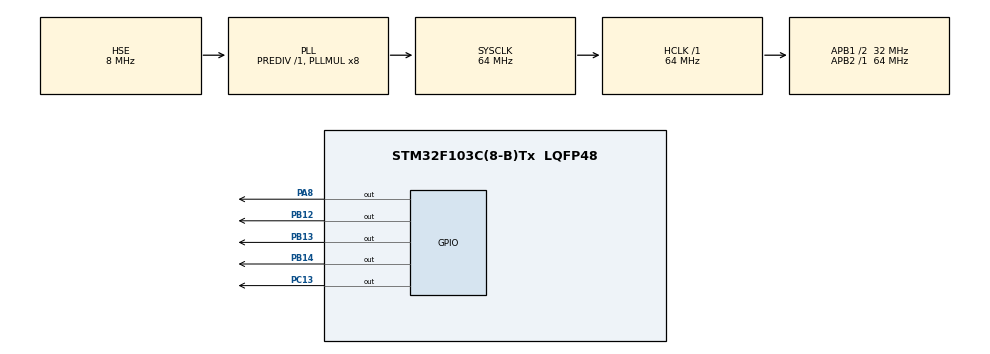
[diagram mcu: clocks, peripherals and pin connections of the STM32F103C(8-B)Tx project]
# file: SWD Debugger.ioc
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Mcu.Family=STM32F1
Mcu.Name=STM32F103C(8-B)Tx
Mcu.Package=LQFP48
NVIC.PriorityGroup=NVIC_PRIORITYGROUP_4
PA13.Mode=Serial_Wire
PA13.Signal=SYS_JTMS-SWDIO
PA14.Mode=Serial_Wire
PA14.Signal=SYS_JTCK-SWCLK
PA8.GPIO_PuPd=GPIO_PULLUP
PA8.GPIO_Speed=GPIO_SPEED_FREQ_HIGH
PA8.PinState=GPIO_PIN_SET
PA8.Signal=GPIO_Output
PB12.GPIO_Speed=GPIO_SPEED_FREQ_HIGH
PB12.PinState=GPIO_PIN_SET
PB12.Signal=GPIO_Output
PB13.GPIO_PuPd=GPIO_PULLUP
PB13.GPIO_Speed=GPIO_SPEED_FREQ_HIGH
PB13.Signal=GPIO_Output
PB14.GPIO_PuPd=GPIO_PULLUP
PB14.GPIO_Speed=GPIO_SPEED_FREQ_HIGH
PB14.PinState=GPIO_PIN_SET
PB14.Signal=GPIO_Output
PC13-TAMPER-RTC.GPIO_PuPd=GPIO_PULLUP
PC13-TAMPER-RTC.PinState=GPIO_PIN_SET
PC13-TAMPER-RTC.Signal=GPIO_Output
PD0-OSC_IN.Mode=HSE-External-Oscillator
PD0-OSC_IN.Signal=RCC_OSC_IN
PD1-OSC_OUT.Mode=HSE-External-Oscillator
PD1-OSC_OUT.Signal=RCC_OSC_OUT
ProjectManager.HeapSize=0x200
ProjectManager.StackSize=0x400
ProjectManager.TargetToolchain=SW4STM32
RCC.AHBFreq_Value=64000000
RCC.APB1CLKDivider=RCC_HCLK_DIV2
RCC.APB1Freq_Value=32000000
RCC.APB1TimFreq_Value=64000000
RCC.APB2Freq_Value=64000000
RCC.APB2TimFreq_Value=64000000
RCC.HCLKFreq_Value=64000000
RCC.PLLMUL=RCC_PLL_MUL8
RCC.PLLSourceVirtual=RCC_PLLSOURCE_HSE
RCC.SYSCLKFreq_VALUE=64000000
RCC.SYSCLKSource=RCC_SYSCLKSOURCE_PLLCLK
RCC.USBFreq_Value=64000000
board=custom

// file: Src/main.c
/**
  ******************************************************************************
  * @file           : main.c
  * @brief          : Main program body
  ******************************************************************************
  ** This notice applies to any and all portions of this file
  * that are not between comment pairs USER CODE BEGIN and
  * USER CODE END. Other portions of this file, whether
  * inserted by the user or by software development tools
  * are owned by their respective copyright owners.
  *
  * COPYRIGHT(c) 2018 STMicroelectronics
  *
  * Redistribution and use in source and binary forms, with or without modification,
  * are permitted provided that the following conditions are met:
  *   1. Redistributions of source code must retain the above copyright notice,
  *      this list of conditions and the following disclaimer.
  *   2. Redistributions in binary form must reproduce the above copyright notice,
  *      this list of conditions and the following disclaimer in the documentation
  *      and/or other materials provided with the distribution.
  *   3. Neither the name of STMicroelectronics nor the names of its contributors
  *      may be used to endorse or promote products derived from this software
  *      without specific prior written permission.
  *
  * THIS SOFTWARE IS PROVIDED BY THE COPYRIGHT HOLDERS AND CONTRIBUTORS "AS IS"
  * AND ANY EXPRESS OR IMPLIED WARRANTIES, INCLUDING, BUT NOT LIMITED TO, THE
  * IMPLIED WARRANTIES OF MERCHANTABILITY AND FITNESS FOR A PARTICULAR PURPOSE ARE
  * DISCLAIMED. IN NO EVENT SHALL THE COPYRIGHT HOLDER OR CONTRIBUTORS BE LIABLE
  * FOR ANY DIRECT, INDIRECT, INCIDENTAL, SPECIAL, EXEMPLARY, OR CONSEQUENTIAL
  * DAMAGES (INCLUDING, BUT NOT LIMITED TO, PROCUREMENT OF SUBSTITUTE GOODS OR
  * SERVICES; LOSS OF USE, DATA, OR PROFITS; OR BUSINESS INTERRUPTION) HOWEVER
  * CAUSED AND ON ANY THEORY OF LIABILITY, WHETHER IN CONTRACT, STRICT LIABILITY,
  * OR TORT (INCLUDING NEGLIGENCE OR OTHERWISE) ARISING IN ANY WAY OUT OF THE USE
  * OF THIS SOFTWARE, EVEN IF ADVISED OF THE POSSIBILITY OF SUCH DAMAGE.
  *
  ******************************************************************************
  */
#include "main.h"
#include "stm32f1xx_hal.h"

/* USER CODE BEGIN Includes */
//#include "debug.h"
#include "swdio.h"

uint16_t swdSwSeq;
uint8_t test8;
uint32_t *bitread=0;
volatile uint32_t *idCode=0;
uint32_t *bitread_lsb;
int testparity;
uint32_t status;

//Configure pin as output/input/open drain
/*
#define	_swdAsOuput()					\
		do{								\
			GPIO_InitTypeDef GPIO_InitStruct;	\
			HAL_GPIO_WritePin(SWD_IO_PORT, GPIO_PIN_8, GPIO_PIN_SET);	\
			GPIO_InitStruct.Pin = GPIO_PIN_8;	\
			GPIO_InitStruct.Mode = GPIO_MODE_OUTPUT_PP;	\
			GPIO_InitStruct.Pull = GPIO_PULLUP;	\
			GPIO_InitStruct.Speed = GPIO_SPEED_FREQ_HIGH; \
			HAL_GPIO_Init(SWD_IO_PORT, &GPIO_InitStruct);		\
		}while (0)

#define	_swdAsInput()					\
		do{								\
			GPIO_InitTypeDef GPIO_InitStruct;	\
			HAL_GPIO_WritePin(SWD_IO_PORT, GPIO_PIN_8, GPIO_PIN_SET);	\
			GPIO_InitStruct.Pin = GPIO_PIN_8;	\
			GPIO_InitStruct.Mode = GPIO_MODE_INPUT;	\
			GPIO_InitStruct.Pull = GPIO_PULLDOWN;	\
			GPIO_InitStruct.Speed = GPIO_SPEED_FREQ_HIGH; \
			HAL_GPIO_Init(SWD_IO_PORT, &GPIO_InitStruct);		\
		}while (0)

#define	_swdAsOuputOpenDrain()					\
		do{								\
			GPIO_InitTypeDef GPIO_InitStruct;	\
			HAL_GPIO_WritePin(SWD_IO_PORT, GPIO_PIN_8, GPIO_PIN_SET);	\
			GPIO_InitStruct.Pin = GPIO_PIN_8;	\
			GPIO_InitStruct.Mode = GPIO_MODE_OUTPUT_OD;	\
			GPIO_InitStruct.Pull = GPIO_PULLUP;	\
			GPIO_InitStruct.Speed = GPIO_SPEED_FREQ_HIGH; \
			HAL_GPIO_Init(SWD_IO_PORT, &GPIO_InitStruct);		\
		}while (0)
*/
/* USER CODE END Includes */

/* USER CODE BEGIN PV */
/* Private variables ---------------------------------------------------------*/

/* USER CODE END PV */

void SystemClock_Config(void);
static void MX_GPIO_Init(void);

/* USER CODE BEGIN PFP */
/* Private function prototypes -----------------------------------------------*/

/* USER CODE END PFP */

int main(void)
{

  /* MCU Configuration----------------------------------------------------------*/

  /* Reset of all peripherals, Initializes the Flash interface and the Systick. */

	HAL_Init();

  /* Configure the system clock */
  SystemClock_Config();

  /* Initialize all configured peripherals */
  MX_GPIO_Init();
  /* USER CODE BEGIN 2 */

  //resetDebugPin();
  //writeTurnAround();
  //testparity = computeParityBit(0x9);
  // All the initialization sequence
  //swdLineReset();
  //swdWriteBits(SW_EQ_CODE,16);
  //bitread = swdReadBits(32,*bitread_lsb);
  //swdLineReset();
  //swdWriteBits(1,2);
  //_swdAsInput();
  //bitread=swdReadBits(3,&idCode);

  lineReset();
  swdWriteBits(SW_EQ_CODE,16);
  lineReset();
  status=SwdApDpRequest(DP_RD_IDCODE,&bitread);
  //status=SwdApDpRequest(DP_RD_IDCODE,&bitread);

  //swdWriteBits(SW_IDCODE_RD,8);
  //bitread = SWDIO_Pin;

  //readTurnAround();
  //bitread=swdReadBits(38);

  //test8= SW_Request(0x01);
  //SW_ShiftPacket(SW_IDCODE_RD,0,0);
  //resetDebugPin();

  // Set the CDBGPWRUPREQ and CSYSPWRUPREQ bits of CTRL/STATUS
  //SW_ShiftPacket(0xA3,0,0x20000000);
  // Write 0x000000F0 to SELECT (select AHB-AP, bank 0xF)
  //SW_ShiftPacket(0xA9,0,0x000000F0);
  // Read the IDR CODE
  //SW_ShiftPacket(0xAF,0,0x000000F0);
  // Write 0x00000000 to SELECT (select AHB-AP, bank 0x0)
  //SW_ShiftPacket(0xA9,0,0x00000000);
  // Set the size field of CSW to 0x2 (32-bit transfer)
  //SW_ShiftPacket(0xAB,0,0x00000010);
  // Start using TAR/DRW to access internal memory
  //SW_ShiftPacket(0xAB,0,0x00000010);

  HAL_Delay(100);
  //bitread = tarWriteandReadAccess(0x20000000,0x12345678);

  // OxEOOEDF4 is the Debug Core Register Selector Register
  //init_ldr();
  //bitread = tarReadAccess(0xE000EDF4);

  // Try to write a data to it
  //writeTurnAround();
  //swdWriteBits(0xA1,8);				// 0x85 when is from LSB
  //readTurnAround();
  //swdReadBits(3);
  //writeTurnAround();
  //swdWriteBits(0x4A4A4A4A,34);		// 0x52 when is from LSB
  //resetDebugPin();
  //idleCycles(2);

  // Read the data from it
  //writeTurnAround();
  //swdWriteBits(0xA1,8);
  //readTurnAround();
  //swdReadBits(38);

  // Read the status flag from the status/control register
  //writeTurnAround();
  //swdWriteBits(SW_STATUS_FLG,8);
  //readTurnAround();
  //swdReadBits(38);
  //writeTurnAround();

  //bitread = returnIDcode(GPIOA,GPIO_PIN_8,GPIO_PIN_14);
  //bitread_lsb = bitread >> 15;
  // Write a data to a debug port
  // The 8 bit sequence : 1

  /* USER CODE END 2 */

  /* Infinite loop */
  while (1)
  {

  }

}

void SystemClock_Config(void)
{

  RCC_OscInitTypeDef RCC_OscInitStruct;
  RCC_ClkInitTypeDef RCC_ClkInitStruct;

    /**Initializes the CPU, AHB and APB busses clocks
    */
  RCC_OscInitStruct.OscillatorType = RCC_OSCILLATORTYPE_HSE;
  RCC_OscInitStruct.HSEState = RCC_HSE_ON;
  RCC_OscInitStruct.HSEPredivValue = RCC_HSE_PREDIV_DIV1;
  RCC_OscInitStruct.HSIState = RCC_HSI_ON;
  RCC_OscInitStruct.PLL.PLLState = RCC_PLL_ON;
  RCC_OscInitStruct.PLL.PLLSource = RCC_PLLSOURCE_HSE;
  RCC_OscInitStruct.PLL.PLLMUL = RCC_PLL_MUL8;
  if (HAL_RCC_OscConfig(&RCC_OscInitStruct) != HAL_OK)
  {
    _Error_Handler(__FILE__, __LINE__);
  }

    /**Initializes the CPU, AHB and APB busses clocks
    */
  RCC_ClkInitStruct.ClockType = RCC_CLOCKTYPE_HCLK|RCC_CLOCKTYPE_SYSCLK
                              |RCC_CLOCKTYPE_PCLK1|RCC_CLOCKTYPE_PCLK2;
  RCC_ClkInitStruct.SYSCLKSource = RCC_SYSCLKSOURCE_PLLCLK;
  RCC_ClkInitStruct.AHBCLKDivider = RCC_SYSCLK_DIV1;
  RCC_ClkInitStruct.APB1CLKDivider = RCC_HCLK_DIV2;
  RCC_ClkInitStruct.APB2CLKDivider = RCC_HCLK_DIV1;

  if (HAL_RCC_ClockConfig(&RCC_ClkInitStruct, FLASH_LATENCY_2) != HAL_OK)
  {
    _Error_Handler(__FILE__, __LINE__);
  }

    /**Configure the Systick interrupt time
    */
  HAL_SYSTICK_Config(HAL_RCC_GetHCLKFreq()/1000);

    /**Configure the Systick
    */
  HAL_SYSTICK_CLKSourceConfig(SYSTICK_CLKSOURCE_HCLK);

  /* SysTick_IRQn interrupt configuration */
  HAL_NVIC_SetPriority(SysTick_IRQn, 0, 0);
}

/** Configure pins as
        * Analog
        * Input
        * Output
        * EVENT_OUT
        * EXTI
*/
static void MX_GPIO_Init(void)
{

  GPIO_InitTypeDef GPIO_InitStruct;

  /* GPIO Ports Clock Enable */
  __HAL_RCC_GPIOC_CLK_ENABLE();
  __HAL_RCC_GPIOD_CLK_ENABLE();
  __HAL_RCC_GPIOB_CLK_ENABLE();
  __HAL_RCC_GPIOA_CLK_ENABLE();

  /*Configure GPIO pin Output Level */
  HAL_GPIO_WritePin(GPIOC, GPIO_PIN_13, GPIO_PIN_SET);

  /*Configure GPIO pin Output Level */
  HAL_GPIO_WritePin(SWD_CLOCK_PORT, GPIO_PIN_12|GPIO_PIN_14, GPIO_PIN_SET);

  /*Configure GPIO pin Output Level */
  HAL_GPIO_WritePin(SWD_CLOCK_PORT, GPIO_PIN_13, GPIO_PIN_RESET);

  /*Configure GPIO pin Output Level */
  HAL_GPIO_WritePin(SWD_IO_PORT, GPIO_PIN_8, GPIO_PIN_SET);

  /*Configure GPIO pin : PC13 */
  GPIO_InitStruct.Pin = GPIO_PIN_13;
  GPIO_InitStruct.Mode = GPIO_MODE_OUTPUT_PP;
  GPIO_InitStruct.Pull = GPIO_PULLUP;
  GPIO_InitStruct.Speed = GPIO_SPEED_FREQ_LOW;
  HAL_GPIO_Init(GPIOC, &GPIO_InitStruct);

  /*Configure GPIO pin : PB12 */
  GPIO_InitStruct.Pin = GPIO_PIN_12;
  GPIO_InitStruct.Mode = GPIO_MODE_OUTPUT_PP;
  GPIO_InitStruct.Pull = GPIO_NOPULL;
  GPIO_InitStruct.Speed = GPIO_SPEED_FREQ_HIGH;
  HAL_GPIO_Init(SWD_CLOCK_PORT, &GPIO_InitStruct);

  /*Configure GPIO pins : PB13 PB14 */
  GPIO_InitStruct.Pin = GPIO_PIN_13|GPIO_PIN_14;
  GPIO_InitStruct.Mode = GPIO_MODE_OUTPUT_PP;
  GPIO_InitStruct.Pull = GPIO_PULLDOWN;
  GPIO_InitStruct.Speed = GPIO_SPEED_FREQ_HIGH;
  HAL_GPIO_Init(SWD_CLOCK_PORT, &GPIO_InitStruct);

  /*Configure GPIO pin : PA8 */
  GPIO_InitStruct.Pin = GPIO_PIN_8;
  GPIO_InitStruct.Mode = GPIO_MODE_OUTPUT_PP;
  GPIO_InitStruct.Pull = GPIO_PULLUP;
  GPIO_InitStruct.Speed = GPIO_SPEED_FREQ_HIGH;
  HAL_GPIO_Init(SWD_IO_PORT, &GPIO_InitStruct);

}

void _Error_Handler(char *file, int line)
{
  while(1)
  {
  }
}

/************************ (C) COPYRIGHT STMicroelectronics *****END OF FILE****/
